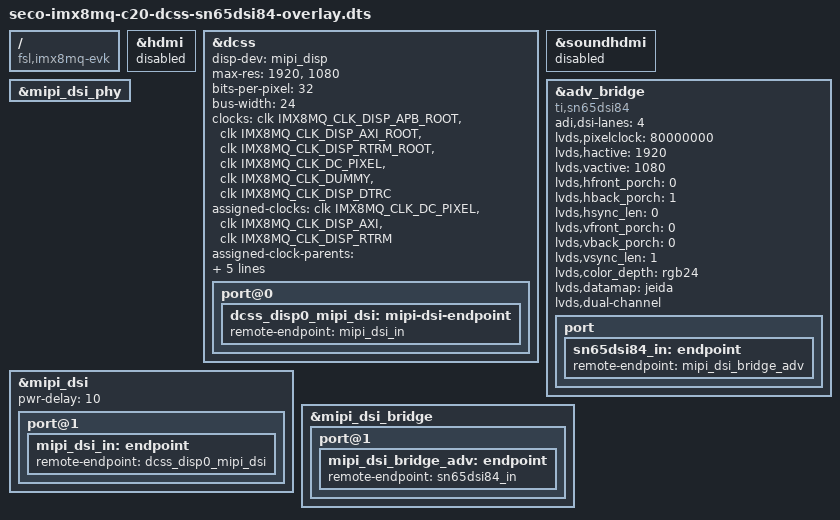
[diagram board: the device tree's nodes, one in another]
/*
 * Copyright 2017 NXP
 *
 * This program is free software; you can redistribute it and/or
 * modify it under the terms of the GNU General Public License
 * as published by the Free Software Foundation; either version 2
 * of the License, or (at your option) any later version.
 *
 * This program is distributed in the hope that it will be useful,
 * but WITHOUT ANY WARRANTY; without even the implied warranty of
 * MERCHANTABILITY or FITNESS FOR A PARTICULAR PURPOSE.  See the
 * GNU General Public License for more details.
 */

#include <dt-bindings/clock/imx8mq-clock.h>

/dts-v1/;
/plugin/;

/ {
        compatible = "fsl,imx8mq-evk","seco,seco-imx8mq-c20", "fsl,imx8mq";

/*  __________________________________________________________________________
 * |                                                                          |
 * |                               WiFi                                       |
 * |__________________________________________________________________________|
 */

        fragment@1 {
                target = <&hdmi>;
                __overlay__ {
			status = "disabled";
		 };
	};

	fragment@2 {
                target = <&dcss>;
                __overlay__ {
                        status = "okay";
			disp-dev = "mipi_disp";
			max-res = <1920>,<1080>;
			bits-per-pixel = <32>;
			bus-width = <24>;

        clocks = <&clk IMX8MQ_CLK_DISP_APB_ROOT>,
                 <&clk IMX8MQ_CLK_DISP_AXI_ROOT>,
                 <&clk IMX8MQ_CLK_DISP_RTRM_ROOT>,
                 <&clk IMX8MQ_CLK_DC_PIXEL>,
                 <&clk IMX8MQ_CLK_DUMMY>,
                 <&clk IMX8MQ_CLK_DISP_DTRC>;
        clock-names = "apb", "axi", "rtrm", "pix_div", "pix_out", "dtrc";
        assigned-clocks = <&clk IMX8MQ_CLK_DC_PIXEL>,
                          <&clk IMX8MQ_CLK_DISP_AXI>,
                          <&clk IMX8MQ_CLK_DISP_RTRM>;
        assigned-clock-parents = <&clk IMX8MQ_VIDEO_PLL1_OUT>,
                                 <&clk IMX8MQ_SYS1_PLL_800M>,
                                 <&clk IMX8MQ_SYS1_PLL_800M>;
        assigned-clock-rates = <594000000>,
                               <800000000>,
                               <400000000>,
                               <400000000>;

			port@0 {
					dcss_disp0_mipi_dsi: mipi-dsi-endpoint {
						remote-endpoint = <&mipi_dsi_in>;
					};
			};
		};
	};
	

        fragment@3 {
                target = <&soundhdmi>;
                __overlay__ {
			status = "disabled";
		 };
	};


	fragment@7 {
                target = <&adv_bridge>;
                __overlay__ {
                        compatible = "ti,sn65dsi84";
			adi,dsi-lanes = <4>;
			lvds,pixelclock = <80000000>; /* Report Single Channel Clock if panel
							is Dual Channel */
			lvds,hactive = <1920>;
			lvds,vactive = <1080>;
			lvds,hfront_porch = <0>;
			lvds,hback_porch = <1>;
			lvds,hsync_len = <0>;
			lvds,vfront_porch = <0>;
			lvds,vback_porch = <0>;
			lvds,vsync_len = <1>;
			lvds,color_depth = "rgb24";
			lvds,datamap = "jeida";
			lvds,dual-channel;
			status = "okay";

			port {
				sn65dsi84_in: endpoint {
					remote-endpoint = <&mipi_dsi_bridge_adv>;
				};
			};
		};
	};
	
	fragment@8 {
                target = <&mipi_dsi_phy>;
                __overlay__ {
                        status = "okay";
                 };
        };

	fragment@9 {
                target = <&mipi_dsi>;
                __overlay__ {
			status = "okay";
			pwr-delay = <10>;

			port@1 {
				mipi_dsi_in: endpoint {
					remote-endpoint = <&dcss_disp0_mipi_dsi>;
				};
			}; 
		};
	};

	fragment@10 {
                target = <&mipi_dsi_bridge>;
                __overlay__ {
                        status = "okay";
			port@1 {
				mipi_dsi_bridge_adv: endpoint {
					remote-endpoint = <&sn65dsi84_in>;
				};
			};
		};
        };

};
